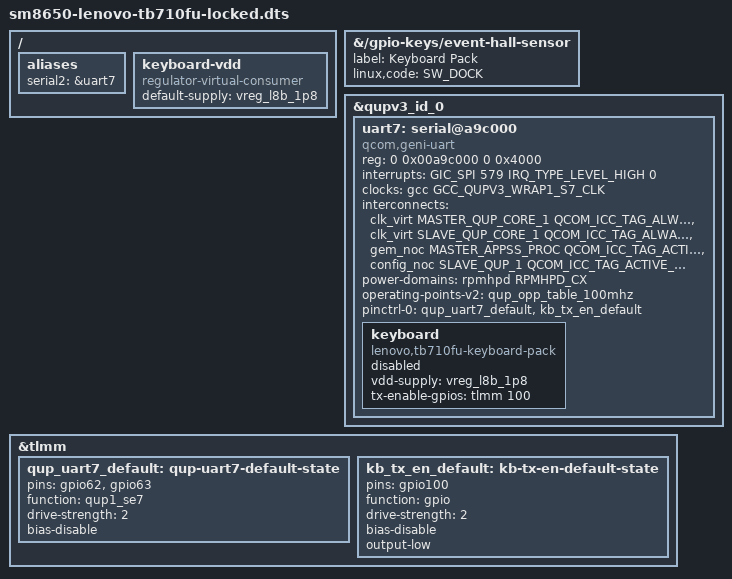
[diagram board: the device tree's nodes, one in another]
// SPDX-License-Identifier: GPL-2.0-only
/*
 * Lenovo TB710FU booted by the stock ABL from A/B slot b (locked bootloader, GKI v4 layout,
 * tb710fu-arch-linux) instead of kShimC: ArmadaOS' board file plus the Lenovo Keyboard Pack.
 *
 * Keyboard Pack (AGENTS.md in tb710fu-arch-linux): 2-wire UART on QUP1 SE7 at
 * 921600 8N1, plug detect on gpio81, host TX enable on gpio100.
 *
 * Pogo VDD = PM8550 LDO8 (L8B). Stock lenovo_keyboard.ko sets exactly 3.300 V and enables it
 * only after plug-in. Here a virtual consumer lets userspace switch it; nothing touches the rail
 * at boot (regulator-boot-on on L8B reset the tablet at 0.37 s, 2026-11-15). Use 3.296 V: on
 * the 8 mV grid and not above stock's 3.300 V (rpmh caches the voltage until the first enable,
 * so the earlier 3.304 V was only ever sent together with that enable).
 */
#include "sm8650-lenovo-tb710fu.dts"

/ {
	aliases {
		serial2 = &uart7;
	};

	/* tb710fu-keyboard: max_microvolts then min_microvolts = 3296000 enables, min = 0 disables */
	keyboard-vdd {
		compatible = "regulator-virtual-consumer";
		default-supply = <&vreg_l8b_1p8>;
	};
};

/* gpio81 is the Keyboard Pack plug detect (stock lenovo_kb plug-gpios), not a lid hall sensor:
 * low = keyboard attached */
&{/gpio-keys/event-hall-sensor} {
	label = "Keyboard Pack";
	linux,code = <SW_DOCK>;
};

&qupv3_id_0 {
	uart7: serial@a9c000 {
		compatible = "qcom,geni-uart";
		reg = <0 0x00a9c000 0 0x4000>;

		interrupts = <GIC_SPI 579 IRQ_TYPE_LEVEL_HIGH 0>;

		clocks = <&gcc GCC_QUPV3_WRAP1_S7_CLK>;
		clock-names = "se";

		interconnects = <&clk_virt MASTER_QUP_CORE_1 QCOM_ICC_TAG_ALWAYS
				 &clk_virt SLAVE_QUP_CORE_1 QCOM_ICC_TAG_ALWAYS>,
				<&gem_noc MASTER_APPSS_PROC QCOM_ICC_TAG_ACTIVE_ONLY
				 &config_noc SLAVE_QUP_1 QCOM_ICC_TAG_ACTIVE_ONLY>;
		interconnect-names = "qup-core",
				     "qup-config";

		power-domains = <&rpmhpd RPMHPD_CX>;
		operating-points-v2 = <&qup_opp_table_100mhz>;

		pinctrl-0 = <&qup_uart7_default>, <&kb_tx_en_default>;
		pinctrl-names = "default";

		/* Kernel driver (kernel/tb710fu-kbpack, module tb710fu-kbpack) in place of the
		 * tb710fu-keyboard daemon: set "okay". The UART then has no tty (serdev). While
		 * disabled, serdev finds no child and ttyHS2 stays for the daemon. */
		keyboard {
			compatible = "lenovo,tb710fu-keyboard-pack";
			vdd-supply = <&vreg_l8b_1p8>;
			tx-enable-gpios = <&tlmm 100 GPIO_ACTIVE_HIGH>;
			status = "disabled";
		};
	};
};

&tlmm {
	qup_uart7_default: qup-uart7-default-state {
		/* TX, RX */
		pins = "gpio62", "gpio63";
		function = "qup1_se7";
		drive-strength = <2>;
		bias-disable;
	};

	/* host -> keyboard TX buffer enable (stock lenovo_kb tx-en-gpios), driven by tb710fu-keyboard */
	kb_tx_en_default: kb-tx-en-default-state {
		pins = "gpio100";
		function = "gpio";
		drive-strength = <2>;
		bias-disable;
		output-low;
	};
};
